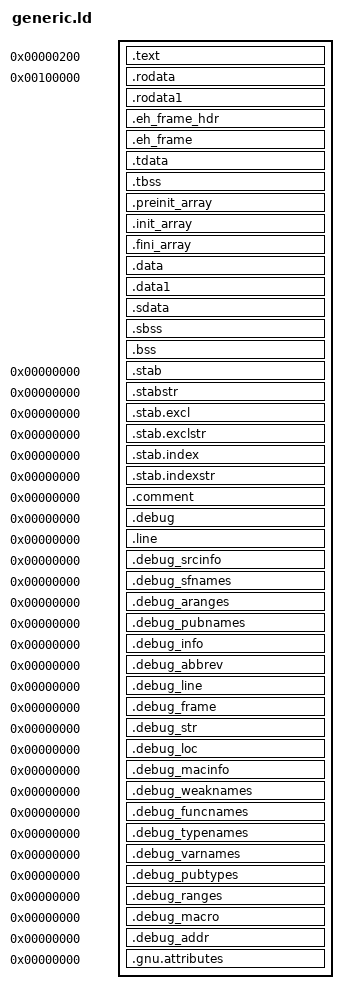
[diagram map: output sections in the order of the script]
/*
 * Copyright (c) 2017-2019, LG Electronics Inc.
 *
 * This program or software including the accompanying associated documentation
 * ("Software") is the proprietary software of LG Electronics Inc. and or its
 * licensors, and may only be used, duplicated, modified or distributed pursuant
 * to the terms and conditions of a separate written license agreement between
 * you and LG Electronics Inc. ("Authorized License"). Except as set forth in an
 * Authorized License, LG Electronics Inc. grants no license (express or implied),
 * rights to use, or waiver of any kind with respect to the Software, and LG
 * Electronics Inc. expressly reserves all rights in and to the Software and all
 * intellectual property therein. If you have no Authorized License, then you
 * have no rights to use the Software in any ways, and should immediately notify
 * LG Electronics Inc. and discontinue all use of the Software.
 *
 * Author:
 *  SeungRyeol Lee <zizztux.lee@lge.com>
 */

OUTPUT_FORMAT("elf32-littleriscv", "elf32-bigriscv", "elf32-littleriscv")
OUTPUT_ARCH(riscv)

ENTRY(_start)


SECTIONS
{
    . = 0x00000200;
    _ftext = .;

    .text :
    {
        *(.text.startup)
        *(.text.init)
        *(.text.init.*)
        *(.text)
        *(.text.*)
        *(.gnu.linkonce.t.*)
    }

    PROVIDE(__etext = .);
    PROVIDE(_etext = .);
    PROVIDE(etext = .);

    . = 0x00100000;

    .rodata :
    {
        *(.rdata)
        *(.rodata)
        *(.rodata.*)
        *(.gnu.linkonce.r.*)
    }
    .rodata1 : { *(.rodata1) }

    .eh_frame_hdr : { *(.eh_frame_hdr) *(.eh_frame_entry .eh_frame_entry.*) }
    .eh_frame : { KEEP(*(.eh_frame)) *(.eh_frame.*) }

    /* Thread Local Storage sections  */
    .tdata :
    {
        PROVIDE_HIDDEN(__tdata_start = .);
        *(.tdata .tdata.* .gnu.linkonce.td.*)
    }
    .tbss : { *(.tbss .tbss.* .gnu.linkonce.tb.*) *(.tcommon) }

    .preinit_array :
    {
        PROVIDE_HIDDEN(__preinit_array_start = .);
        KEEP(*(.preinit_array))
        PROVIDE_HIDDEN(__preinit_array_end = .);
    }
    .init_array :
    {
        PROVIDE_HIDDEN(__init_array_start = .);
        KEEP(*(SORT_BY_INIT_PRIORITY(.init_array.*)))
        KEEP(*(.init_array))
        PROVIDE_HIDDEN(__init_array_end = .);
    }
    .fini_array :
    {
        PROVIDE_HIDDEN(__fini_array_start = .);
        KEEP(*(SORT_BY_INIT_PRIORITY(.fini_array.*)))
        KEEP(*(.fini_array))
        PROVIDE_HIDDEN(__fini_array_end = .);
    }

    . = ALIGN(16);
    _fdata = .;

    .data :
    {
        __DATA_BEGIN__ = .;
        *(.data)
        *(.data.*)
        *(.gnu.linkonce.d.*)
    }
    .data1 : { *(.data1) }
    .sdata :
    {
        __SDATA_BEGIN__ = .;
        *(.srodata.cst16) *(.srodata.cst8) *(.srodata.cst4) *(.srodata.cst2) *(.srodata .srodata.*)
        *(.sdata .sdata.* .gnu.linkonce.s.*)
    }
    _edata = .;
    PROVIDE(edata = .);

    . = .;

    __bss_start = .;
    .sbss :
    {
        *(.sbss)
        *(.sbss.*)
        *(.gnu.linkonce.sb.*)
        *(.scommon)
    }
    .bss :
    {
        *(.bss)
        *(.bss.*)
        *(.gnu.linkonce.b.*)
        *(COMMON)
    }
    . = ALIGN(4);
    __BSS_END__ = .;
    __global_pointer$ = MIN(__SDATA_BEGIN__ + 0x800, MAX(__DATA_BEGIN__ + 0x800, __BSS_END__ - 0x800));

    _end = .;
    PROVIDE(end = .);

    __stack_top = 0x00100000 + __intmem_size;

    /* Stabs debugging sections.  */
    .stab          0 : { *(.stab) }
    .stabstr       0 : { *(.stabstr) }
    .stab.excl     0 : { *(.stab.excl) }
    .stab.exclstr  0 : { *(.stab.exclstr) }
    .stab.index    0 : { *(.stab.index) }
    .stab.indexstr 0 : { *(.stab.indexstr) }
    .comment       0 : { *(.comment) }
    /* DWARF debug sections.
       Symbols in the DWARF debugging sections are relative to the beginning
       of the section so we begin them at 0. */
    /* DWARF 1 */
    .debug          0 : { *(.debug) }
    .line           0 : { *(.line) }
    /* GNU DWARF 1 extensions */
    .debug_srcinfo  0 : { *(.debug_srcinfo) }
    .debug_sfnames  0 : { *(.debug_sfnames) }
    /* DWARF 1.1 and DWARF 2 */
    .debug_aranges  0 : { *(.debug_aranges) }
    .debug_pubnames 0 : { *(.debug_pubnames) }
    /* DWARF 2 */
    .debug_info     0 : { *(.debug_info .gnu.linkonce.wi.*) }
    .debug_abbrev   0 : { *(.debug_abbrev) }
    .debug_line     0 : { *(.debug_line .debug_line.* .debug_line_end) }
    .debug_frame    0 : { *(.debug_frame) }
    .debug_str      0 : { *(.debug_str) }
    .debug_loc      0 : { *(.debug_loc) }
    .debug_macinfo  0 : { *(.debug_macinfo) }
    /* SGI/MIPS DWARF 2 extensions */
    .debug_weaknames 0 : { *(.debug_weaknames) }
    .debug_funcnames 0 : { *(.debug_funcnames) }
    .debug_typenames 0 : { *(.debug_typenames) }
    .debug_varnames  0 : { *(.debug_varnames) }
    /* DWARF 3 */
    .debug_pubtypes 0 : { *(.debug_pubtypes) }
    .debug_ranges   0 : { *(.debug_ranges) }
    /* DWARF Extension.  */
    .debug_macro    0 : { *(.debug_macro) }
    .debug_addr     0 : { *(.debug_addr) }
    .gnu.attributes 0 : { KEEP(*(.gnu.attributes)) }
    /DISCARD/ : { *(.note.GNU-stack) *(.gnu_debuglink) *(.gnu.lto_*) }
}

ASSERT((__stack_top > _end), "No room left for the stack.");
